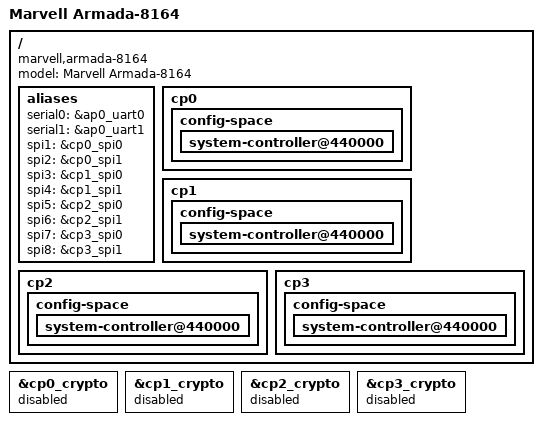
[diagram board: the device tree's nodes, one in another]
// SPDX-License-Identifier: (GPL-2.0+ OR MIT)
/*
 * Copyright (C) 2018 Marvell Technology Group Ltd.
 *
 * Device Tree file for Marvell Armada-8164 SoC, made of two AP810 and
 * four CP110.
 */

/*
 * Device Tree file for Marvell Armada-8164 SoC.
 */

#include "armada-common.dtsi"
#include "armada-8kp.dtsi"
#include "armada-ap810-ap0.dtsi"

#define AP_NUM				0
#define AP810_BASE			0xe8000000
#define AP810_GIC_ITS_BASE		0xf040000
#include "armada-ap810-octa-core.dtsi"

/* CP110-0 Settings */
#define CP110_NUM		0

#include "armada-cp110.dtsi"

#undef CP110_NUM

/* AP0 CP1 IO
 * 0x88_0000_0000 - 0x88_ffff_ffff - internal CFG (4GB)
 * 0x89_0000_0000 - 0x8a_ffff_ffff - PEX0 (8GB)
 * 0x8b_0000_0000 - 0x8c_ffff_ffff - PEX1 (8GB)
 * 0x8d_0000_0000 - 0x8e_ffff_ffff - PEX2 (8GB)
 */
#define CP110_NUM		1

#include "armada-cp110.dtsi"

#undef CP110_NUM

#undef AP_NUM
#undef AP810_BASE
#undef AP810_GIC_ITS_BASE

#define AP_NUM				1
#define AP810_BASE			0xe4000000
/*
 * AP1 gic its base
 *(0xe4000000+0x3040000) = (0xdc000000+0xb040000) = 0xe7040000
 */
#define AP810_GIC_ITS_BASE		0xb040000
#include "armada-ap810-octa-core.dtsi"

/* CP110-2 Settings */
#define CP110_NUM		2

#include "armada-cp110.dtsi"

#undef CP110_NUM

/* AP1 CP1 IO
 * 0xa5_0000_0000 - 0xa5_ffff_ffff - internal CFG (4GB)
 * 0xa6_0000_0000 - 0xa7_ffff_ffff - PEX0 (8GB)
 * 0xa8_0000_0000 - 0xa9_ffff_ffff - PEX1 (8GB)
 * 0xaa_0000_0000 - 0xab_ffff_ffff - PEX2 (8GB)
 */
#define CP110_NUM		3

#include "armada-cp110.dtsi"

#undef CP110_NUM

#undef CP110_BASE
#undef CP110_PCIE_MEM_SIZE
#undef CP110_PCIEx_CPU_IO_BASE
#undef CP110_PCIEx_CPU_MEM_BASE
#undef CP110_PCIEx_BUS_IO_BASE
#undef CP110_PCIEx_BUS_MEM_BASE
#undef CP110_PCIE_BUS_MEM_CFG

/* AP810 definitions are used in CP110 dtsi files, so un-define them after defining it's connected CPs */
#undef AP_NUM
#undef AP810_BASE
#undef AP810_GIC_ITS_BASE

/ {
	model = "Marvell Armada-8164";
	compatible = "marvell,armada-8164", "marvell,armada-ap810-octa",
				"marvell,armada-ap810";

	aliases {
		serial0 = &ap0_uart0;
		serial1 = &ap0_uart1;
		spi1 = &cp0_spi0;
		spi2 = &cp0_spi1;
		spi3 = &cp1_spi0;
		spi4 = &cp1_spi1;
		spi5 = &cp2_spi0;
		spi6 = &cp2_spi1;
		spi7 = &cp3_spi0;
		spi8 = &cp3_spi1;
	};

	/* Delete unsupported interfaces from CP nodes:
	 *	1. GPIO in CP requires a pinctrl driver support,
	 *	   which is currently not suitable for AP810.
	 */
	cp0 {
		config-space {
			system-controller@440000 {
				/delete-node/ gpio@100;
				/delete-node/ gpio@140;
			};
		};
	};
	cp1 {
		config-space {
			system-controller@440000 {
				/delete-node/ gpio@100;
				/delete-node/ gpio@140;
			};
		};
	};
	cp2 {
		config-space {
			system-controller@440000 {
				/delete-node/ gpio@100;
				/delete-node/ gpio@140;
			};
		};
	};
	cp3 {
		config-space {
			system-controller@440000 {
				/delete-node/ gpio@100;
				/delete-node/ gpio@140;
			};
		};
	};
};

&cp0_crypto {
	status = "disabled";
};

&cp1_crypto {
	status = "disabled";
};

&cp2_crypto {
	status = "disabled";
};

&cp3_crypto {
	status = "disabled";
};
